# MIMXRT1052 register map
Vendor: nxp.com; File version: 1.0
CPU: CM7 r0p1, little endian, MPU, FPU, VTOR, 4 interrupt priority bits
Registers are 32-bit, read-write, reset 0x0 unless marked. A register's access mark holds for its fields unless they carry their own. Offsets are from the block's base; [hi:lo] are bit positions; {n}, {i} and the like mark numbered series; 'fields as' and 'values as' point back to an identical list.

## IOMUXC_GPR
Base 0x400AC000; register names take the prefix IOMUXC_GPR_
0x00 GPR0 ro — GPR0 General Purpose Register
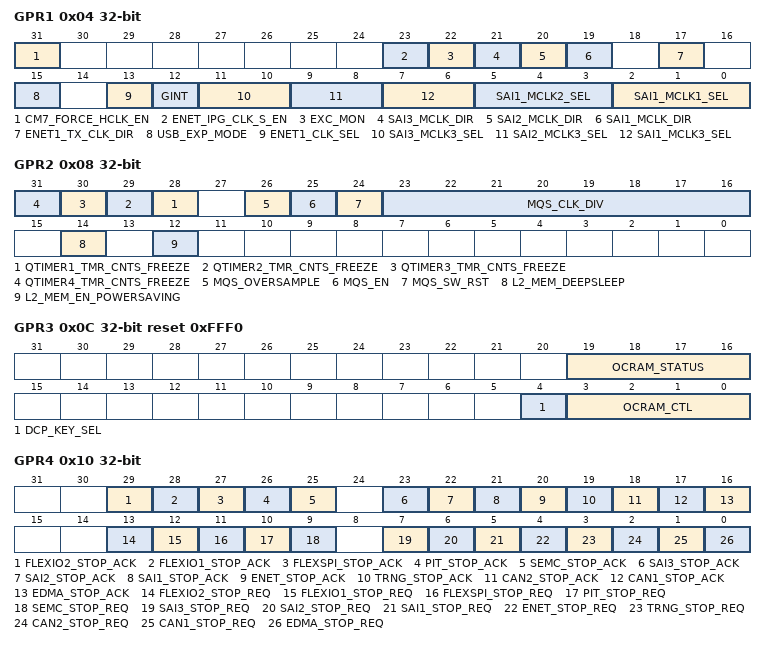
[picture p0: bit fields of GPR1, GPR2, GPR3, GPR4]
0x04 GPR1 — GPR1 General Purpose Register
  [31] CM7_FORCE_HCLK_EN — ARM CM7 platform AHB clock enable
    0=AHB clock is not running (gated); 1=AHB clock is running (enabled)
  [23] ENET_IPG_CLK_S_EN — ENET ipg_clk_s clock gating enable
    0=ipg_clk_s is gated when there is no IPS access; 1=ipg_clk_s is always on
  [22] EXC_MON — Exclusive monitor response select of illegal command
    0=OKAY response; 1=SLVError response
  [21] SAI3_MCLK_DIR — sai3.MCLK signal direction control
    0=sai3.MCLK is input signal; 1=sai3.MCLK is output signal
  [20] SAI2_MCLK_DIR — sai2.MCLK signal direction control
    0=sai2.MCLK is input signal; 1=sai2.MCLK is output signal
  [19] SAI1_MCLK_DIR — sai1.MCLK signal direction control
    0=sai1.MCLK is input signal; 1=sai1.MCLK is output signal
  [17] ENET1_TX_CLK_DIR — ENET1_TX_CLK data direction control when ENET_REF_CLK1 ALT is selected.
    0=ENET1_TX_CLK output driver is disabled and ENET_REF_CLK1 is a clock input; 1=ENET1_TX_CLK output driver is enabled and ENET_REF_CLK1 is an output driven by ref_enetpll0
  [15] USB_EXP_MODE — USB Exposure mode
    0=Exposure mode is disabled; 1=Exposure mode is enabled
  [13] ENET1_CLK_SEL — ENET1 reference clock mode select.
    0=ENET1 TX reference clock driven by ref_enetpll0. This clock is also output to pins via the IOMUX. ENET_REF_CLK1 function.; 1=Gets ENET1 TX reference clock from the ENET1_TX_CLK pin. In this use case, an external OSC provides the clock for both the external PHY and the internal controller.
  [12] GINT — Global interrupt bit (connected to ARM M7 IRQ#41 and GPC)
    0=Global interrupt request is not asserted; 1=Global interrupt request is asserted
  [11:10] SAI3_MCLK3_SEL — SAI3 MCLK3 source select
    0=ccm.spdif0_clk_root; 1=iomux.spdif_tx_clk2; 2=spdif.spdif_srclk; 3=spdif.spdif_outclock
  [9:8] SAI2_MCLK3_SEL — SAI2 MCLK3 source select
    values as SAI3_MCLK3_SEL
  [7:6] SAI1_MCLK3_SEL — SAI1 MCLK3 source select
    values as SAI3_MCLK3_SEL
  [5:3] SAI1_MCLK2_SEL — SAI1 MCLK2 source select
    0=ccm.ssi1_clk_root; 1=ccm.ssi2_clk_root; 2=ccm.ssi3_clk_root; 3=iomux.sai1_ipg_clk_sai_mclk; 4=iomux.sai2_ipg_clk_sai_mclk; 5=iomux.sai3_ipg_clk_sai_mclk
  [2:0] SAI1_MCLK1_SEL — SAI1 MCLK1 source select
    values as SAI1_MCLK2_SEL
0x08 GPR2 — GPR2 General Purpose Register
  [n+27] QTIMER{n}_TMR_CNTS_FREEZE (n=1..4) — QTIMER{n} timer counter freeze
    0=timer counter work normally; 1=reset counter and ouput flags
  [26] MQS_OVERSAMPLE — Used to control the PWM oversampling rate compared with mclk.
    0=32; 1=64
  [25] MQS_EN — MQS enable.
    0=Disable MQS; 1=Enable MQS
  [24] MQS_SW_RST — MQS software reset
    0=Exit software reset for MQS; 1=Enable software reset for MQS
  [23:16] MQS_CLK_DIV — Divider ratio control for mclk from hmclk. mclk frequency = 1/(n+1) * hmclk frequency.
    {v}=DIVIDE_{v+1} (mclk frequency = 1/{v+1} * hmclk frequency) (v=0..255)
  [14] L2_MEM_DEEPSLEEP — control how memory enter Deep Sleep mode (shutdown periphery power, but maintain memory contents, outputs of memory are pulled low)
    0=no force sleep control supported, memory deep sleep mode only entered when whole system in stop mode; 1=force memory into deep sleep mode
  [12] L2_MEM_EN_POWERSAVING — enable power saving features on memory
    0=none memory power saving features enabled, SHUTDOWN/DEEPSLEEP/LIGHTSLEEP will have no effect; 1=memory power saving features enabled, set SHUTDOWN/DEEPSLEEP/LIGHTSLEEP(priority high to low) to enable power saving levels
0x0C GPR3 reset 0xFFF0 — GPR3 General Purpose Register
  [19:16] OCRAM_STATUS ro — This field shows the OCRAM pipeline settings status, controlled by OCRAM_CTL bits respectively
    0=read data pipeline configuration valid; 1=read data pipeline control bit changed
  [4] DCP_KEY_SEL — Select 128-bit dcp key from 256-bit key from snvs/ocotp
    0=Select [127:0] from snvs/ocotp key as dcp key; 1=Select [255:128] from snvs/ocotp key as dcp key
  [3:0] OCRAM_CTL — OCRAM_CTL[3] - write address pipeline control bit
0x10 GPR4 — GPR4 General Purpose Register
  [29] FLEXIO2_STOP_ACK ro — FLEXIO2 stop acknowledge
    0=FLEXIO2 stop acknowledge is not asserted; 1=FLEXIO2 stop acknowledge is asserted (FLEXIO2 is in STOP mode)
  [28] FLEXIO1_STOP_ACK ro — FLEXIO1 stop acknowledge
    0=FLEXIO1 stop acknowledge is not asserted; 1=FLEXIO1 stop acknowledge is asserted
  [27] FLEXSPI_STOP_ACK ro — FLEXSPI stop acknowledge
    0=FLEXSPI stop acknowledge is not asserted; 1=FLEXSPI stop acknowledge is asserted
  [26] PIT_STOP_ACK ro — PIT stop acknowledge
    0=PIT stop acknowledge is not asserted; 1=PIT stop acknowledge is asserted
  [25] SEMC_STOP_ACK ro — SEMC stop acknowledge
    0=SEMC stop acknowledge is not asserted; 1=SEMC stop acknowledge is asserted
  [23] SAI3_STOP_ACK ro — SAI3 stop acknowledge
    0=SAI3 stop acknowledge is not asserted; 1=SAI3 stop acknowledge is asserted
  [22] SAI2_STOP_ACK ro — SAI2 stop acknowledge
    0=SAI2 stop acknowledge is not asserted; 1=SAI2 stop acknowledge is asserted
  [21] SAI1_STOP_ACK ro — SAI1 stop acknowledge
    0=SAI1 stop acknowledge is not asserted; 1=SAI1 stop acknowledge is asserted
  [20] ENET_STOP_ACK ro — ENET stop acknowledge.
    0=ENET stop acknowledge is not asserted; 1=ENET stop acknowledge is asserted
  [19] TRNG_STOP_ACK ro — TRNG stop acknowledge
    0=TRNG stop acknowledge is not asserted; 1=TRNG stop acknowledge is asserted
  [18] CAN2_STOP_ACK ro — CAN2 stop acknowledge.
    0=CAN2 stop acknowledge is not asserted; 1=CAN2 stop acknowledge is asserted
  [17] CAN1_STOP_ACK ro — CAN1 stop acknowledge.
    0=CAN1 stop acknowledge is not asserted; 1=CAN1 stop acknowledge is asserted
  [16] EDMA_STOP_ACK ro — EDMA stop acknowledge. This is a status (read-only) bit
    0=EDMA stop acknowledge is not asserted; 1=EDMA stop acknowledge is asserted (EDMA is in STOP mode)
  [13] FLEXIO2_STOP_REQ — FlexIO2 stop request.
    0=stop request off; 1=stop request on
  [12] FLEXIO1_STOP_REQ — FlexIO1 stop request.
    0=stop request off; 1=stop request on
  [11] FLEXSPI_STOP_REQ — FlexSPI stop request.
    0=stop request off; 1=stop request on
  [10] PIT_STOP_REQ — PIT stop request.
    0=stop request off; 1=stop request on
  [9] SEMC_STOP_REQ — SEMC stop request.
    0=stop request off; 1=stop request on
  [7] SAI3_STOP_REQ — SAI3 stop request.
    0=stop request off; 1=stop request on
  [6] SAI2_STOP_REQ — SAI2 stop request.
    0=stop request off; 1=stop request on
  [5] SAI1_STOP_REQ — SAI1 stop request.
    0=stop request off; 1=stop request on
  [4] ENET_STOP_REQ — ENET stop request.
    0=stop request off; 1=stop request on
  [3] TRNG_STOP_REQ — TRNG stop request.
    0=stop request off; 1=stop request on
  [2] CAN2_STOP_REQ — CAN2 stop request.
    0=stop request off; 1=stop request on
  [1] CAN1_STOP_REQ — CAN1 stop request.
    0=stop request off; 1=stop request on
  [0] EDMA_STOP_REQ — EDMA stop request.
    0=stop request off; 1=stop request on
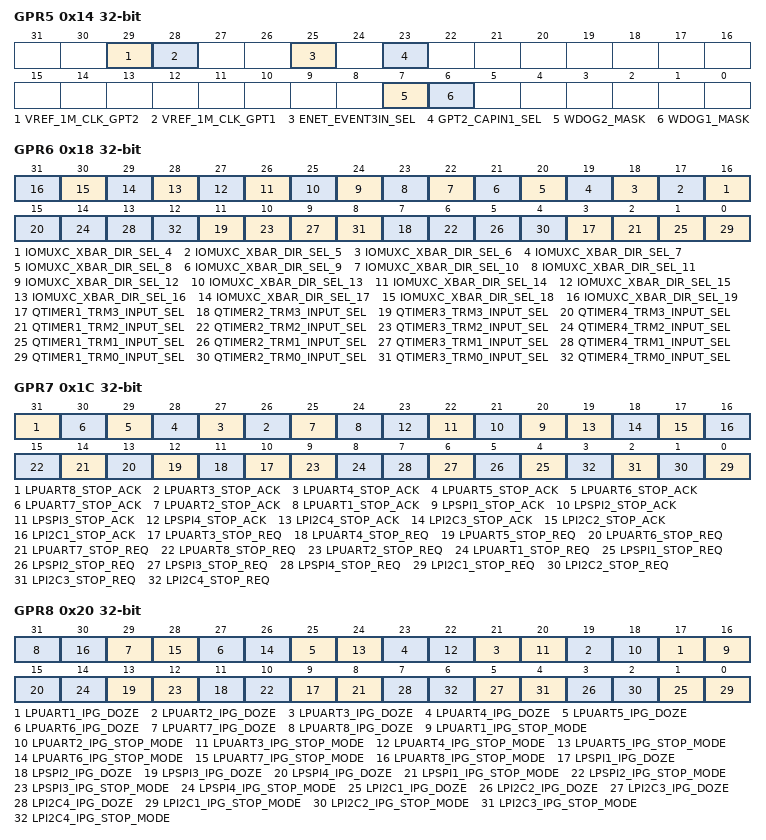
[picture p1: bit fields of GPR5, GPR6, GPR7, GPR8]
0x14 GPR5 — GPR5 General Purpose Register
  [29] VREF_1M_CLK_GPT2 — GPT2 1 MHz clock source select
    0=GPT2 ipg_clk_highfreq driven by IPG_PERCLK; 1=GPT2 ipg_clk_highfreq driven by anatop 1 MHz clock
  [28] VREF_1M_CLK_GPT1 — GPT1 1 MHz clock source select
    0=GPT1 ipg_clk_highfreq driven by IPG_PERCLK; 1=GPT1 ipg_clk_highfreq driven by anatop 1 MHz clock
  [25] ENET_EVENT3IN_SEL — ENET input timer event3 source select
    0=event3 source input from pad; 1=event3 source input from gpt2.ipp_do_cmpout1
  [23] GPT2_CAPIN1_SEL — GPT2 input capture channel 1 source select
    0=source from pad; 1=source from enet1.ipp_do_mac0_timer[3]
  [7] WDOG2_MASK — WDOG2 Timeout Mask
    0=WDOG2 Timeout behaves normally; 1=WDOG2 Timeout is masked
  [6] WDOG1_MASK — WDOG1 Timeout Mask
    0=WDOG1 Timeout behaves normally; 1=WDOG1 Timeout is masked
0x18 GPR6 — GPR6 General Purpose Register
  [n+12] IOMUXC_XBAR_DIR_SEL_{n} (n=4..19) — IOMUXC XBAR_INOUT{n} function direction select
    0=XBAR_INOUT as input; 1=XBAR_INOUT as output
  [4n-1] QTIMER{n}_TRM3_INPUT_SEL (n=1..4) — QTIMER{n} TMR3 input select
    0=input from IOMUX; 1=input from XBAR
  [4n-2] QTIMER{n}_TRM2_INPUT_SEL (n=1..4) — QTIMER{n} TMR2 input select
    0=input from IOMUX; 1=input from XBAR
  [4n-3] QTIMER{n}_TRM1_INPUT_SEL (n=1..4) — QTIMER{n} TMR1 input select
    0=input from IOMUX; 1=input from XBAR
  [4n-4] QTIMER{n}_TRM0_INPUT_SEL (n=1..4) — QTIMER{n} TMR0 input select
    0=input from IOMUX; 1=input from XBAR
0x1C GPR7 — GPR7 General Purpose Register
  [31] LPUART8_STOP_ACK ro — LPUART8 stop acknowledge
    0=stop acknowledge is not asserted; 1=stop acknowledge is asserted (the module is in Stop mode)
  [n+23] LPUART{n}_STOP_ACK ro (n=3..7) — LPUART{n} stop acknowledge
    0=stop acknowledge is not asserted; 1=stop acknowledge is asserted
  [25] LPUART2_STOP_ACK ro — LPUART1 stop acknowledge
    values as LPUART3_STOP_ACK
  [24] LPUART1_STOP_ACK ro — LPUART1 stop acknowledge
    values as LPUART3_STOP_ACK
  [n+19] LPSPI{n}_STOP_ACK ro (n=1..4) — LPSPI{n} stop acknowledge
    values as LPUART3_STOP_ACK
  [19] LPI2C4_STOP_ACK ro — LPI2C4 stop acknowledge
    values as LPUART3_STOP_ACK
  [18] LPI2C3_STOP_ACK ro — LPI2C3 stop acknowledge
    values as LPUART3_STOP_ACK
  [17] LPI2C2_STOP_ACK ro — LPI2C2 stop acknowledge
    values as LPUART3_STOP_ACK
  [16] LPI2C1_STOP_ACK ro — LPI2C1 stop acknowledge
    values as LPUART8_STOP_ACK
  [n+7] LPUART{n}_STOP_REQ (n=3..8) — LPUART{n} stop request
    0=stop request off; 1=stop request on
  [9] LPUART2_STOP_REQ — LPUART1 stop request
    0=stop request off; 1=stop request on
  [8] LPUART1_STOP_REQ — LPUART1 stop request
    0=stop request off; 1=stop request on
  [n+3] LPSPI{n}_STOP_REQ (n=1..4) — LPSPI{n} stop request
    0=stop request off; 1=stop request on
  [n-1] LPI2C{n}_STOP_REQ (n=1..4) — LPI2C{n} stop request
    0=stop request off; 1=stop request on
0x20 GPR8 — GPR8 General Purpose Register
  [2n+15] LPUART{n}_IPG_DOZE (n=1..8) — LPUART{n} ipg_doze mode
    0=not in doze mode; 1=in doze mode
  [2n+14] LPUART{n}_IPG_STOP_MODE (n=1..8) — LPUART{n} stop mode selection, cannot change when ipg_stop is asserted.
    0=the module is functional in Stop mode; 1=the module is NOT functional in Stop mode, when this bit is equal to 1 and ipg_stop is asserted
  [2n+7] LPSPI{n}_IPG_DOZE (n=1..4) — LPSPI{n} ipg_doze mode
    0=not in doze mode; 1=in doze mode
  [2n+6] LPSPI{n}_IPG_STOP_MODE (n=1..4) — LPSPI{n} stop mode selection, cannot change when ipg_stop is asserted.
    values as LPUART1_IPG_STOP_MODE
  [2n-1] LPI2C{n}_IPG_DOZE (n=1..4) — LPI2C{n} ipg_doze mode
    0=not in doze mode; 1=in doze mode
  [2n-2] LPI2C{n}_IPG_STOP_MODE (n=1..4) — LPI2C{n} stop mode selection, cannot change when ipg_stop is asserted.
    values as LPUART1_IPG_STOP_MODE
0x24 GPR9 ro — GPR9 General Purpose Register
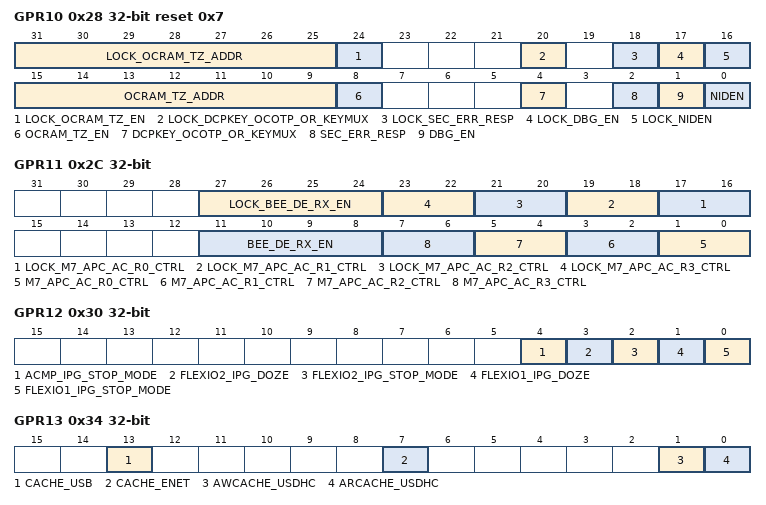
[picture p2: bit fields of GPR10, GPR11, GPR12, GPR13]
0x28 GPR10 reset 0x7 — GPR10 General Purpose Register
  [31:25] LOCK_OCRAM_TZ_ADDR — Lock OCRAM_TZ_ADDR field for changes
    0=Field is not locked; 1=Field is locked (read access only)
  [24] LOCK_OCRAM_TZ_EN — Lock OCRAM_TZ_EN field for changes
    0=Field is not locked; 1=Field is locked (read access only)
  [20] LOCK_DCPKEY_OCOTP_OR_KEYMUX — Lock DCP Key OCOTP/Key MUX selection bit
    0=Field is not locked; 1=Field is locked (read access only)
  [18] LOCK_SEC_ERR_RESP — Lock SEC_ERR_RESP field for changes
    0=Field is not locked; 1=Field is locked (read access only)
  [17] LOCK_DBG_EN — Lock DBG_EN field for changes
    0=Field is not locked; 1=Field is locked (read access only)
  [16] LOCK_NIDEN — Lock NIDEN field for changes
    0=Field is not locked; 1=Field is locked (read access only)
  [15:9] OCRAM_TZ_ADDR — OCRAM TrustZone (TZ) start address
  [8] OCRAM_TZ_EN — OCRAM TrustZone (TZ) enable.
    0=The TrustZone feature is disabled. Entire OCRAM space is available for all access types (secure/non-secure/user/supervisor).; 1=The TrustZone feature is enabled. Access to address in the range specified by [ENDADDR:STARTADDR] follows the execution mode access policy described in CSU chapter.
  [4] DCPKEY_OCOTP_OR_KEYMUX — DCP Key selection bit.
    0=Select key from Key MUX (SNVS/OTPMK); 1=Select key from OCOTP (SW_GP2)
  [2] SEC_ERR_RESP — Security error response enable for all security gaskets (on both AHB and AXI buses)
    0=OKEY response; 1=SLVError (default)
  [1] DBG_EN — ARM invasive debug enable
    0=Debug turned off; 1=Debug enabled (default)
  [0] NIDEN — ARM non-secure (non-invasive) debug enable
    0=Debug turned off; 1=Debug enabled (default)
0x2C GPR11 — GPR11 General Purpose Register
  [27:24] LOCK_BEE_DE_RX_EN — Lock BEE_DE_RX_EN[n] (n = 3 to 0) field for changes
  [2n+17:2n+16] LOCK_M7_APC_AC_R{n}_CTRL (n=0..3) — Lock M7_APC_AC_R{n}_CTRL field for changes
  [11:8] BEE_DE_RX_EN — BEE data decryption of memory region-n (n = 3 to 0)
  [2n+1:2n] M7_APC_AC_R{n}_CTRL (n=0..3) — Access control of memory region-{n}
    0=No access protection; 1=M7 debug protection enabled; 2=FlexSPI access protection; 3=Both M7 debug and FlexSPI access are protected
0x30 GPR12 — GPR12 General Purpose Register
  [4] ACMP_IPG_STOP_MODE — ACMP stop mode selection. Cannot change when ipg_stop is asserted.
    0=ACMP is functional in Stop mode; 1=When this bit is equal to 1'b1 and ipg_stop is asserted, ACMP is not functional in Stop mode
  [3] FLEXIO2_IPG_DOZE — FLEXIO2 ipg_doze mode
    0=FLEXIO2 is not in doze mode; 1=FLEXIO2 is in doze mode
  [2] FLEXIO2_IPG_STOP_MODE — FlexIO2 stop mode selection. Cannot change when ipg_stop is asserted.
    0=FlexIO2 is functional in Stop mode; 1=When this bit is equal to 1'b1 and ipg_stop is asserted, FlexIO2 is not functional in Stop mode
  [1] FLEXIO1_IPG_DOZE — FLEXIO1 ipg_doze mode
    0=FLEXIO1 is not in doze mode; 1=FLEXIO1 is in doze mode
  [0] FLEXIO1_IPG_STOP_MODE — FlexIO1 stop mode selection. Cannot change when ipg_stop is asserted.
    0=FlexIO1 is functional in Stop mode; 1=When this bit is equal to 1'b1 and ipg_stop is asserted, FlexIO1 is not functional in Stop mode
0x34 GPR13 — GPR13 General Purpose Register
  [13] CACHE_USB — USB block cacheable attribute value of AXI transactions
    0=Cacheable attribute is off for read/write transactions; 1=Cacheable attribute is on for read/write transactions
  [7] CACHE_ENET — ENET block cacheable attribute value of AXI transactions
    values as CACHE_USB
  [1] AWCACHE_USDHC — uSDHC block cacheable attribute value of AXI write transactions
    0=Cacheable attribute is off for write transactions; 1=Cacheable attribute is on for write transactions
  [0] ARCACHE_USDHC — uSDHC block cacheable attribute value of AXI read transactions
    0=Cacheable attribute is off for read transactions; 1=Cacheable attribute is on for read transactions
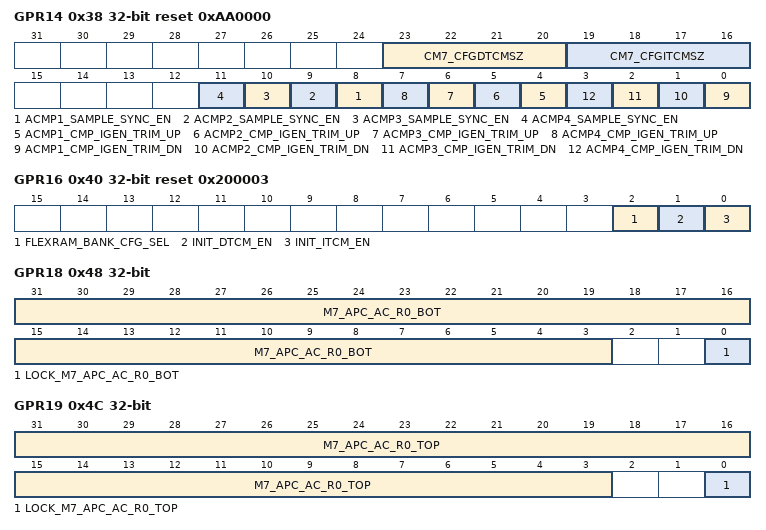
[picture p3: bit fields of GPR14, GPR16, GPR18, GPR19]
0x38 GPR14 reset 0xAA0000 — GPR14 General Purpose Register
  [23:20] CM7_CFGDTCMSZ — DTCM total size configuration
    0=0 KB (No DTCM); 3=4 KB; 4=8 KB; 5=16 KB; 6=32 KB; 7=64 KB; 8=128 KB; 9=256 KB; 10=512 KB
  [19:16] CM7_CFGITCMSZ — ITCM total size configuration
    0=0 KB (No ITCM); 3=4 KB; 4=8 KB; 5=16 KB; 6=32 KB; 7=64 KB; 8=128 KB; 9=256 KB; 10=512 KB
  [n+7] ACMP{n}_SAMPLE_SYNC_EN (n=1..4) — ACMP{n} sample_lv source select
    0=select XBAR output; 1=select synced sample_lv
  [n+3] ACMP{n}_CMP_IGEN_TRIM_UP (n=1..4) — increases ACMP{n} internal bias current by 30%
    0=no increase; 1=increases
  [n-1] ACMP{n}_CMP_IGEN_TRIM_DN (n=1..4) — reduces ACMP{n} internal bias current by 30%
    0=no reduce; 1=reduces
0x3C GPR15 ro reset 0xFFFFFFFF — GPR15 General Purpose Register
0x40 GPR16 reset 0x200003 — GPR16 General Purpose Register
  [2] FLEXRAM_BANK_CFG_SEL — FlexRAM bank config source select
    0=use fuse value to config; 1=use FLEXRAM_BANK_CFG to config
  [1] INIT_DTCM_EN — DTCM enable initialization out of reset
    0=DTCM is disabled; 1=DTCM is enabled
  [0] INIT_ITCM_EN — ITCM enable initialization out of reset
    0=ITCM is disabled; 1=ITCM is enabled
0x44 GPR17 — GPR17 General Purpose Register
  [31:0] FLEXRAM_BANK_CFG — FlexRAM bank config value
0x48 GPR18 — GPR18 General Purpose Register
  [31:3] M7_APC_AC_R0_BOT — APC end address of memory region-0
  [0] LOCK_M7_APC_AC_R0_BOT — lock M7_APC_AC_R0_BOT field for changes
    0=Register field [31:1] is not locked; 1=Register field [31:1] is locked (read access only)
0x4C GPR19 — GPR19 General Purpose Register
  [31:3] M7_APC_AC_R0_TOP — APC start address of memory region-0
  [0] LOCK_M7_APC_AC_R0_TOP — lock M7_APC_AC_R0_TOP field for changes
    values as GPR18.LOCK_M7_APC_AC_R0_BOT
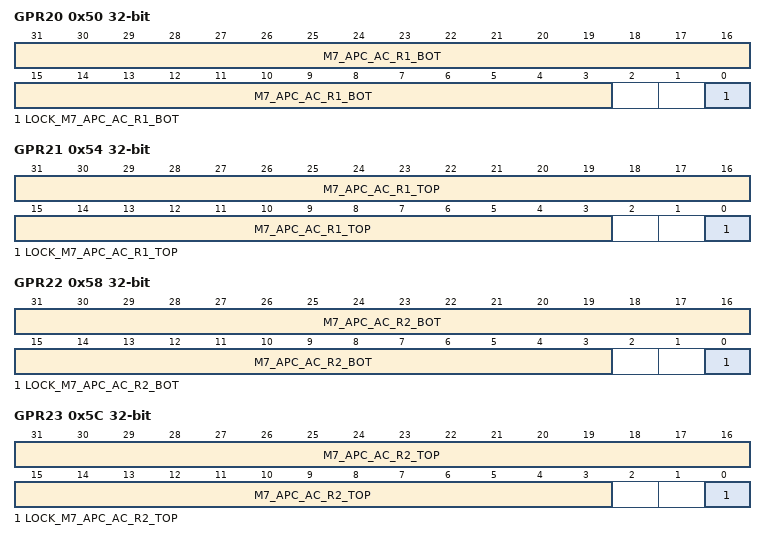
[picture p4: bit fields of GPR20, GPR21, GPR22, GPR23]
0x50 GPR20 — GPR20 General Purpose Register
  [31:3] M7_APC_AC_R1_BOT — APC end address of memory region-1
  [0] LOCK_M7_APC_AC_R1_BOT — lock M7_APC_AC_R1_BOT field for changes
    values as GPR18.LOCK_M7_APC_AC_R0_BOT
0x54 GPR21 — GPR21 General Purpose Register
  [31:3] M7_APC_AC_R1_TOP — APC start address of memory region-1
  [0] LOCK_M7_APC_AC_R1_TOP — lock M7_APC_AC_R1_TOP field for changes
    values as GPR18.LOCK_M7_APC_AC_R0_BOT
0x58 GPR22 — GPR22 General Purpose Register
  [31:3] M7_APC_AC_R2_BOT — APC end address of memory region-2
  [0] LOCK_M7_APC_AC_R2_BOT — lock M7_APC_AC_R2_BOT field for changes
    values as GPR18.LOCK_M7_APC_AC_R0_BOT
0x5C GPR23 — GPR23 General Purpose Register
  [31:3] M7_APC_AC_R2_TOP — APC start address of memory region-2
  [0] LOCK_M7_APC_AC_R2_TOP — lock M7_APC_AC_R2_TOP field for changes
    values as GPR18.LOCK_M7_APC_AC_R0_BOT
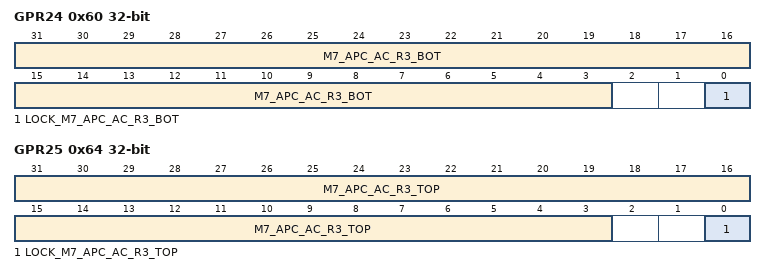
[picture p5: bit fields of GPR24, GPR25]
0x60 GPR24 — GPR24 General Purpose Register
  [31:3] M7_APC_AC_R3_BOT — APC end address of memory region-3
  [0] LOCK_M7_APC_AC_R3_BOT — lock M7_APC_AC_R3_BOT field for changes
    values as GPR18.LOCK_M7_APC_AC_R0_BOT
0x64 GPR25 — GPR25 General Purpose Register
  [31:3] M7_APC_AC_R3_TOP — APC start address of memory region-3
  [0] LOCK_M7_APC_AC_R3_TOP — lock M7_APC_AC_R3_TOP field for changes
    values as GPR18.LOCK_M7_APC_AC_R0_BOT
